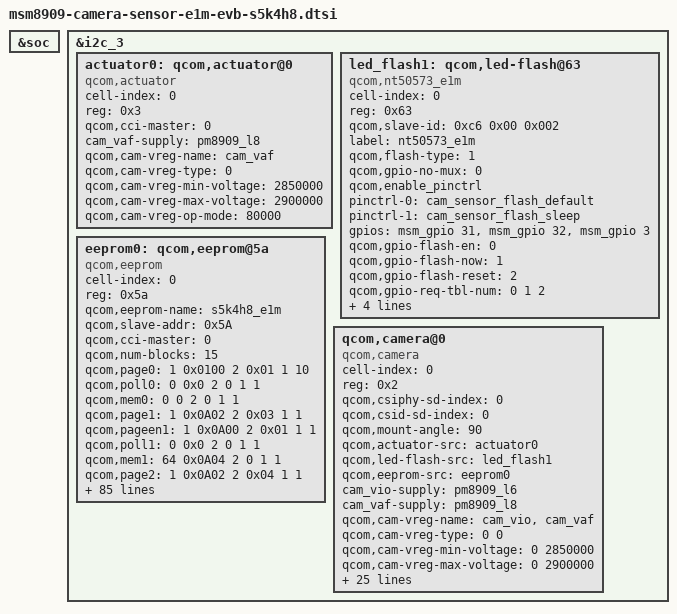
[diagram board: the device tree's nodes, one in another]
/*
 * Copyright (c) 2014, The Linux Foundation. All rights reserved.
 *
 * This program is free software; you can redistribute it and/or modify
 * it under the terms of the GNU General Public License version 2 and
 * only version 2 as published by the Free Software Foundation.
 *
 * This program is distributed in the hope that it will be useful,
 * but WITHOUT ANY WARRANTY; without even the implied warranty of
 * MERCHANTABILITY or FITNESS FOR A PARTICULAR PURPOSE.  See the
 * GNU General Public License for more details.
 */

&soc {
};

&i2c_3 {
	actuator0: qcom,actuator@0 {
		cell-index = <0>;
		reg = <0x3>;
		compatible = "qcom,actuator";
		qcom,cci-master = <0>;
		cam_vaf-supply = <&pm8909_l8>;
		qcom,cam-vreg-name = "cam_vaf";
		qcom,cam-vreg-type = <0>;
		qcom,cam-vreg-min-voltage = <2850000>;
		qcom,cam-vreg-max-voltage = <2900000>;
		qcom,cam-vreg-op-mode = <80000>;
		status = "ok";
	};

	led_flash1:qcom,led-flash@63 {
		cell-index = <0>;
		reg = <0x63>;
		qcom,slave-id = <0xc6 0x00 0x002>;
		compatible = "qcom,nt50573_e1m";
		label = "nt50573_e1m";
		qcom,flash-type = <1>;
		qcom,gpio-no-mux = <0>;
		qcom,enable_pinctrl;
		pinctrl-names = "cam_flash_default", "cam_flash_suspend";
		pinctrl-0 = <&cam_sensor_flash_default>;
		pinctrl-1 = <&cam_sensor_flash_sleep>;
		gpios = <&msm_gpio 31 0>,
			<&msm_gpio 32 0>,
			<&msm_gpio 3 0>;
		qcom,gpio-flash-en = <0>;
		qcom,gpio-flash-now = <1>;
		qcom,gpio-flash-reset = <2>;
		qcom,gpio-req-tbl-num = <0 1 2>;
		qcom,gpio-req-tbl-flags = <0 0 1>;
		qcom,gpio-req-tbl-label = "FLASH_EN",
			"FLASH_NOW",
			"FLASH_RESET";
		qcom,cci-master = <0>;
	};

	eeprom0: qcom,eeprom@5a{
		cell-index = <0>;
		reg = <0x5a>;
		qcom,eeprom-name = "s5k4h8_e1m";
		compatible = "qcom,eeprom";
		qcom,slave-addr = <0x5A>;
		qcom,cci-master = <0>;
		qcom,num-blocks = <15>;

		/*streaming on*/
		qcom,page0 = <1 0x0100 2 0x01 1 10>;
		qcom,poll0 = <0 0x0 2 0 1 1>;
		qcom,mem0 = <0 0 2 0 1 1>;

		/*set the PAGE3 of OTP*/
		/*read enable*/
		/*read 64byte buffer of page*/
		qcom,page1 = <1 0x0A02 2 0x03 1 1>;
		qcom,pageen1 = <1 0x0A00 2 0x01 1 1>;
		qcom,poll1 = <0 0x0 2 0 1 1>;
		qcom,mem1 = <64 0x0A04 2 0 1 1>;

		/*set the PAGE4 of OTP*/
		/*read enable*/
		/*read 64byte buffer of page*/
		qcom,page2 = <1 0x0A02 2 0x04 1 1>;
		qcom,pageen2 = <1 0x0A00 2 0x01 1 1>;
		qcom,poll2 = <0 0x0 2 0 1 1>;
		qcom,mem2 = <64 0x0A04 2 0 1 1>;

		/*set the PAGE5 of OTP*/
		/*read enable*/
		/*read 64byte buffer of page*/
		qcom,page3 = <1 0x0A02 2 0x05 1 1>;
		qcom,pageen3 = <1 0x0A00 2 0x01 1 1>;
		qcom,poll3 = <0 0x0 2 0 1 1>;
		qcom,mem3 = <64 0x0A04 2 0 1 1>;

		/*set the PAGE6 of OTP*/
		/*read enable*/
		/*read 64byte buffer of page*/
		qcom,page4 = <1 0x0A02 2 0x06 1 1>;
		qcom,pageen4 = <1 0x0A00 2 0x01 1 1>;
		qcom,poll4 = <0 0x0 2 0 1 1>;
		qcom,mem4 = <64 0x0A04 2 0 1 1>;

		/*set the PAGE7 of OTP*/
		/*read enable*/
		/*read 64byte buffer of page*/
		qcom,page5 = <1 0x0A02 2 0x07 1 1>;
		qcom,pageen5 = <1 0x0A00 2 0x01 1 1>;
		qcom,poll5 = <0 0x0 2 0 1 1>;
		qcom,mem5 = <64 0x0A04 2 0 1 1>;

		/*set the PAGE8 of OTP*/
		/*read enable*/
		/*read 64byte buffer of page*/
		qcom,page6 = <1 0x0A02 2 0x08 1 1>;
		qcom,pageen6 = <1 0x0A00 2 0x01 1 1>;
		qcom,poll6 = <0 0x0 2 0 1 1>;
		qcom,mem6 = <64 0x0A04 2 0 1 1>;

		/*set the PAGE9 of OTP*/
		/*read enable*/
		/*read 64byte buffer of page*/
		qcom,page7 = <1 0x0A02 2 0x09 1 1>;
		qcom,pageen7 = <1 0x0A00 2 0x01 1 1>;
		qcom,poll7 = <0 0x0 2 0 1 1>;
		qcom,mem7 = <64 0x0A04 2 0 1 1>;

		/*set the PAGE10 of OTP*/
		/*read enable*/
		/*read 64byte buffer of page*/
		qcom,page8 = <1 0x0A02 2 0x0A 1 1>;
		qcom,pageen8 = <1 0x0A00 2 0x01 1 1>;
		qcom,poll8 = <0 0x0 2 0 1 1>;
		qcom,mem8 = <64 0x0A04 2 0 1 1>;

		/*set the PAGE11 of OTP*/
		/*read enable*/
		/*read 64byte buffer of page*/
		qcom,page9 = <1 0x0A02 2 0x0B 1 1>;
		qcom,pageen9 = <1 0x0A00 2 0x01 1 1>;
		qcom,poll9 = <0 0x0 2 0 1 1>;
		qcom,mem9 = <64 0x0A04 2 0 1 1>;

		/*set the PAGE12 of OTP*/
		/*read enable*/
		/*read 64byte buffer of page*/
		qcom,page10 = <1 0x0A02 2 0x0C 1 1>;
		qcom,pageen10 = <1 0x0A00 2 0x01 1 1>;
		qcom,poll10 = <0 0x0 2 0 1 1>;
		qcom,mem10 = <64 0x0A04 2 0 1 1>;

		/*set the PAGE13 of OTP*/
		/*read enable*/
		/*read 64byte buffer of page*/
		qcom,page11 = <1 0x0A02 2 0x0D 1 1>;
		qcom,pageen11 = <1 0x0A00 2 0x01 1 1>;
		qcom,poll11 = <0 0x0 2 0 1 1>;
		qcom,mem11 = <64 0x0A04 2 0 1 1>;

		/*set the PAGE14 of OTP*/
		/*read enable*/
		/*read 64byte buffer of page*/
		qcom,page12 = <1 0x0A02 2 0x0E 1 1>;
		qcom,pageen12 = <1 0x0A00 2 0x01 1 1>;
		qcom,poll12 = <0 0x0 2 0 1 1>;
		qcom,mem12 = <64 0x0A04 2 0 1 1>;

		/*set the PAGE15 of OTP*/
		/*read enable*/
		/*read 64byte buffer of page*/
		qcom,page13 = <1 0x0A02 2 0x0F 1 1>;
		qcom,pageen13 = <1 0x0A00 2 0x01 1 1>;
		qcom,poll13 = <0 0x0 2 0 1 1>;
		qcom,mem13 = <64 0x0A04 2 0 1 1>;

		/*streaming off*/
		qcom,page14 = <1 0x0100 2 0x00 1 1>;
		qcom,poll14 = <0 0x0 2 0 1 1>;
		qcom,mem14 = <0 0 2 0 1 1>;

		cam_vio-supply = <&pm8909_l6>;
		qcom,cam-vreg-name = "cam_vio";
		qcom,cam-vreg-type = <0>;
		qcom,cam-vreg-min-voltage = <0>;
		qcom,cam-vreg-max-voltage = <0>;
		qcom,cam-vreg-op-mode = <0>;
		qcom,enable_pinctrl;
		pinctrl-names = "cam_default", "cam_suspend";
		pinctrl-0 = <&cam_sensor_mclk0_default &cam_sensor_rear_default>;
		pinctrl-1 = <&cam_sensor_mclk0_sleep &cam_sensor_rear_sleep>;
		gpios = <&msm_gpio 26 0>,
			<&msm_gpio 35 0>,
			<&msm_gpio 34 0>, /*for evb*/
			<&msm_gpio 8 0>,
			<&msm_gpio 9 0>,
			<&msm_gpio 58 0>;
		qcom,gpio-reset = <1>;
		qcom,gpio-standby = <2>; /*for evb*/
		qcom,gpio-vana = <3>;
		qcom,gpio-vio = <4>;
		qcom,gpio-vdig = <5>;
		qcom,gpio-req-tbl-num = <0 1 2 3 4 5>;
		qcom,gpio-req-tbl-flags = <1 0 0 0 0 0>;
		qcom,gpio-req-tbl-label = "CAMIF_MCLK",
			"CAM_RESET1",
			"CAM_STANDBY", /*for evb*/
			"CAM_VANA",
			"CAM_VIO",
			"CAM_VDIG";
		qcom,cam-power-seq-type = "sensor_vreg",
                        "sensor_gpio","sensor_gpio",
			"sensor_gpio","sensor_gpio",
			"sensor_gpio","sensor_clk";
		qcom,cam-power-seq-val = "cam_vio",
			"sensor_gpio_vio","sensor_gpio_vana",
			"sensor_gpio_vdig","sensor_gpio_reset",
			"sensor_gpio_standby","sensor_cam_mclk" ;
		qcom,cam-power-seq-cfg-val = <0 1 1 1 1 1 23880000>;
		qcom,cam-power-seq-delay = <1 1 1 2 1 1 10>;
		clocks = <&clock_gcc clk_mclk0_clk_src>,
			<&clock_gcc clk_gcc_camss_mclk0_clk>;
		clock-names = "cam_src_clk", "cam_clk";
		status = "ok";
	};

	qcom,camera@0 {
		cell-index = <0>;
		compatible = "qcom,camera";
		reg = <0x2>;
		qcom,csiphy-sd-index = <0>;
		qcom,csid-sd-index = <0>;
		qcom,mount-angle = <90>;
		qcom,actuator-src = <&actuator0>;
		qcom,led-flash-src = <&led_flash1>;
		qcom,eeprom-src = <&eeprom0>;
		cam_vio-supply = <&pm8909_l6>;
		cam_vaf-supply = <&pm8909_l8>;
		qcom,cam-vreg-name = "cam_vio", "cam_vaf";
		qcom,cam-vreg-type = <0 0>;
		qcom,cam-vreg-min-voltage = <0 2850000>;
		qcom,cam-vreg-max-voltage = <0 2900000>;
		qcom,cam-vreg-op-mode = <0 100000>;
		pinctrl-names = "cam_default", "cam_suspend";
		pinctrl-0 = <&cam_sensor_mclk0_default &cam_sensor_rear_default>;
		pinctrl-1 = <&cam_sensor_mclk0_sleep &cam_sensor_rear_sleep>;
		gpios = <&msm_gpio 26 0>,
			<&msm_gpio 35 0>,
			<&msm_gpio 34 0>, /*for evb*/
			<&msm_gpio 8 0>,
			<&msm_gpio 9 0>,
			<&msm_gpio 58 0>,
			<&msm_gpio 33 0>,
			<&msm_gpio 21 0>;
		qcom,gpio-reset = <1>;
		qcom,gpio-standby = <2>; /*for evb*/
		qcom,gpio-vana = <3>;
		qcom,gpio-vio = <4>;
		qcom,gpio-vdig = <5>;
		qcom,gpio-custom1 = <6>;
		qcom,gpio-custom2 = <7>;
		qcom,gpio-req-tbl-num = <0 1 2 3 4 5 6 7>;
		qcom,gpio-req-tbl-flags = <1 0 0 0 0 0 0 0>;
		qcom,gpio-req-tbl-label = "CAMIF_MCLK",
			"CAM_RESET1",
			"CAM_STANDBY", /*for evb*/
			"CAM_VANA",
			"CAM_VIO",
			"CAM_VDIG",
			"CAM_MIPI_SEL",
			"CAM_MIPI_OE";
		qcom,sensor-position = <0>;
		qcom,sensor-mode = <0>;
		qcom,cci-master = <0>;
		clocks = <&clock_gcc clk_mclk0_clk_src>,
				<&clock_gcc clk_gcc_camss_mclk0_clk>;
		clock-names = "cam_src_clk", "cam_clk";
		status = "ok";
	};
};
